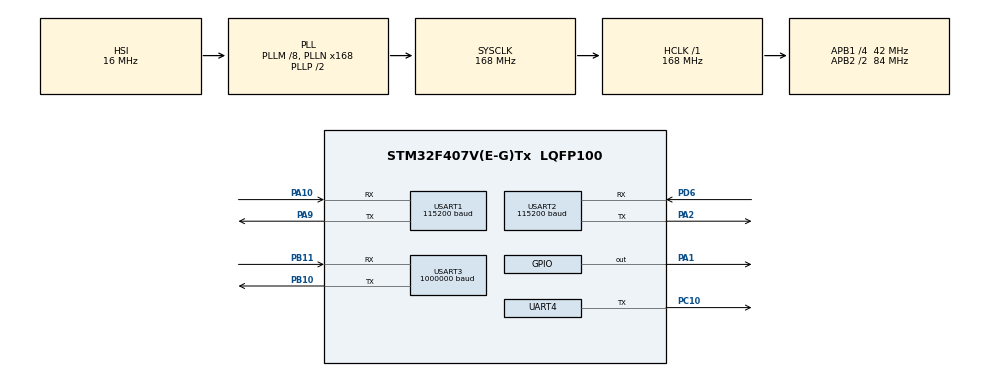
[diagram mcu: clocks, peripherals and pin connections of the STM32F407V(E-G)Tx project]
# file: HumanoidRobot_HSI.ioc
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Dma.Request0=USART1_RX
Dma.Request1=USART2_RX
Dma.Request2=USART3_TX
Dma.Request3=USART3_RX
Dma.USART1_RX.0.Direction=DMA_PERIPH_TO_MEMORY
Dma.USART1_RX.0.FIFOMode=DMA_FIFOMODE_DISABLE
Dma.USART1_RX.0.Instance=DMA2_Stream2
Dma.USART1_RX.0.MemDataAlignment=DMA_MDATAALIGN_BYTE
Dma.USART1_RX.0.MemInc=DMA_MINC_ENABLE
Dma.USART1_RX.0.Mode=DMA_CIRCULAR
Dma.USART1_RX.0.PeriphDataAlignment=DMA_PDATAALIGN_BYTE
Dma.USART1_RX.0.PeriphInc=DMA_PINC_DISABLE
Dma.USART1_RX.0.Priority=DMA_PRIORITY_HIGH
Dma.USART2_RX.1.Direction=DMA_PERIPH_TO_MEMORY
Dma.USART2_RX.1.FIFOMode=DMA_FIFOMODE_DISABLE
Dma.USART2_RX.1.Instance=DMA1_Stream5
Dma.USART2_RX.1.MemDataAlignment=DMA_MDATAALIGN_BYTE
Dma.USART2_RX.1.MemInc=DMA_MINC_ENABLE
Dma.USART2_RX.1.Mode=DMA_CIRCULAR
Dma.USART2_RX.1.PeriphDataAlignment=DMA_PDATAALIGN_BYTE
Dma.USART2_RX.1.PeriphInc=DMA_PINC_DISABLE
Dma.USART2_RX.1.Priority=DMA_PRIORITY_MEDIUM
Dma.USART3_TX.2.Direction=DMA_MEMORY_TO_PERIPH
Dma.USART3_TX.2.FIFOMode=DMA_FIFOMODE_DISABLE
Dma.USART3_TX.2.Instance=DMA1_Stream3
Dma.USART3_TX.2.MemDataAlignment=DMA_MDATAALIGN_BYTE
Dma.USART3_TX.2.MemInc=DMA_MINC_ENABLE
Dma.USART3_TX.2.Mode=DMA_NORMAL
Dma.USART3_TX.2.PeriphDataAlignment=DMA_PDATAALIGN_BYTE
Dma.USART3_TX.2.PeriphInc=DMA_PINC_DISABLE
Dma.USART3_TX.2.Priority=DMA_PRIORITY_MEDIUM
Dma.USART3_RX.3.Direction=DMA_PERIPH_TO_MEMORY
Dma.USART3_RX.3.FIFOMode=DMA_FIFOMODE_DISABLE
Dma.USART3_RX.3.Instance=DMA1_Stream1
Dma.USART3_RX.3.MemDataAlignment=DMA_MDATAALIGN_BYTE
Dma.USART3_RX.3.MemInc=DMA_MINC_ENABLE
Dma.USART3_RX.3.Mode=DMA_CIRCULAR
Dma.USART3_RX.3.PeriphDataAlignment=DMA_PDATAALIGN_BYTE
Dma.USART3_RX.3.PeriphInc=DMA_PINC_DISABLE
Dma.USART3_RX.3.Priority=DMA_PRIORITY_MEDIUM
FREERTOS.Tasks01=IMUTask,32,256,IMU_Task,As external,NULL,Dynamic,NULL,NULL;CameraTask,32,384,Camera_Task,As external,NULL,Dynamic,NULL,NULL;ServoTask,24,256,ServoTask,As external,NULL,Dynamic,NULL,NULL;RobotTask,24,512,RobotTask,As external,NULL,Dynamic,NULL,NULL;DebugTask,8,256,Debug_Task,As external,NULL,Dynamic,NULL,NULL
FREERTOS.configTOTAL_HEAP_SIZE=20480
Mcu.Family=STM32F4
Mcu.Name=STM32F407V(E-G)Tx
Mcu.Package=LQFP100
NVIC.DMA1_Stream1_IRQn=true\:5\:0\:false\:false\:true\:true\:false\:true\:true
NVIC.DMA1_Stream3_IRQn=true\:5\:0\:false\:false\:true\:true\:false\:true\:true
NVIC.DMA1_Stream5_IRQn=true\:5\:0\:false\:false\:true\:true\:false\:true\:true
NVIC.DMA2_Stream2_IRQn=true\:5\:0\:false\:false\:true\:true\:false\:true\:true
NVIC.PriorityGroup=NVIC_PRIORITYGROUP_4
NVIC.TIM6_DAC_IRQn=true\:15\:0\:false\:false\:true\:false\:false\:true\:true
NVIC.TimeBase=TIM6_DAC_IRQn
NVIC.TimeBaseIP=TIM6
NVIC.USART1_IRQn=true\:5\:0\:false\:false\:true\:false\:true\:true\:true
NVIC.USART2_IRQn=true\:5\:0\:false\:false\:true\:false\:true\:true\:true
NVIC.USART3_IRQn=true\:5\:0\:false\:false\:true\:false\:true\:true\:true
PA1.GPIO_PuPd=GPIO_PULLUP
PA1.PinState=GPIO_PIN_SET
PA1.Signal=GPIO_Output
PA10.Mode=Asynchronous
PA10.Signal=USART1_RX
PA13.Mode=Serial_Wire
PA13.Signal=SYS_JTMS-SWDIO
PA14.Mode=Serial_Wire
PA14.Signal=SYS_JTCK-SWCLK
PA2.Mode=Asynchronous
PA2.Signal=USART2_TX
PD6.Mode=Asynchronous
PD6.Signal=USART2_RX
PA9.Mode=Asynchronous
PA9.Signal=USART1_TX
PB10.Mode=Asynchronous
PB10.Signal=USART3_TX
PB11.Mode=Asynchronous
PB11.Signal=USART3_RX
PC10.Mode=Asynchronous
PC10.Signal=UART4_TX
PH0-OSC_IN.Mode=HSE-External-Oscillator
PH0-OSC_IN.Signal=RCC_OSC_IN
PH1-OSC_OUT.Mode=HSE-External-Oscillator
PH1-OSC_OUT.Signal=RCC_OSC_OUT
ProjectManager.HeapSize=0x200
ProjectManager.StackSize=0x800
ProjectManager.TargetToolchain=MDK-ARM V5.32
RCC.48MHZClocksFreq_Value=84000000
RCC.AHBFreq_Value=168000000
RCC.APB1CLKDivider=RCC_HCLK_DIV4
RCC.APB1Freq_Value=42000000
RCC.APB1TimFreq_Value=84000000
RCC.APB2CLKDivider=RCC_HCLK_DIV2
RCC.APB2Freq_Value=84000000
RCC.APB2TimFreq_Value=168000000
RCC.CortexFreq_Value=168000000
RCC.HCLKFreq_Value=168000000
RCC.HSE_VALUE=12000000
RCC.HSI_VALUE=16000000
RCC.LSE_VALUE=32768
RCC.PLLM=8
RCC.PLLN=168
RCC.PLLQ=4
RCC.PLLSourceVirtual=RCC_PLLSOURCE_HSI
RCC.SYSCLKFreq_VALUE=168000000
RCC.SYSCLKSource=RCC_SYSCLKSOURCE_PLLCLK
RCC.VCOOutputFreq_Value=336000000
UART4.BaudRate=115200
UART4.VirtualMode=Asynchronous
UART4.Mode=MODE_TX
USART1.BaudRate=115200
USART1.VirtualMode=VM_ASYNC
USART2.BaudRate=115200
USART2.VirtualMode=VM_ASYNC
USART3.BaudRate=1000000
USART3.VirtualMode=VM_ASYNC
VP_FREERTOS_VS_CMSIS_V2.Mode=CMSIS_V2
VP_SYS_VS_tim6.Mode=TIM6
board=custom

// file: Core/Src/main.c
/* USER CODE BEGIN Header */
/**
  ******************************************************************************
  * @file           : main.c
  * @brief          : Main program body
  ******************************************************************************
  * @attention
  *
  * Copyright (c) 2026 STMicroelectronics.
  * All rights reserved.
  *
  * This software is licensed under terms that can be found in the LICENSE file
  * in the root directory of this software component.
  * If no LICENSE file comes with this software, it is provided AS-IS.
  *
  ******************************************************************************
  */
/* USER CODE END Header */
#include "main.h"
#include "cmsis_os.h"
#include "dma.h"
#include "usart.h"
#include "gpio.h"

void SystemClock_Config(void);
void MX_FREERTOS_Init(void);

int main(void)
{

  /* MCU Configuration--------------------------------------------------------*/

  /* Reset of all peripherals, Initializes the Flash interface and the Systick. */
  HAL_Init();

  /* Configure the system clock */
  SystemClock_Config();

  /* Initialize all configured peripherals */
  MX_GPIO_Init();
  MX_DMA_Init();
  MX_USART1_UART_Init();
  MX_USART2_UART_Init();
  MX_USART3_UART_Init();
  MX_UART4_Init();
  /* USER CODE BEGIN 2 */
    HAL_UART_Transmit(&huart4, (uint8_t *)"UART4 OK\r\n", 10U, 100U);
    {
      static const char bootInfo[] =
        "[BOOT] HumanoidRobot_HSI PA1=HIGH DEBUG=PC10\r\n"
        "[CLOCK] HSI->PLL SYSCLK=168MHz APB1=42MHz APB2=84MHz\r\n";
      HAL_UART_Transmit(&huart4, (uint8_t *)bootInfo,
                        (uint16_t)(sizeof(bootInfo) - 1U), 100U);
    }
  /* USER CODE END 2 */

  /* Init scheduler */
  osKernelInitialize();  /* Call init function for freertos objects (in cmsis_os2.c) */
  MX_FREERTOS_Init();

  /* Start scheduler */
  osKernelStart();

  /* We should never get here as control is now taken by the scheduler */

  /* Infinite loop */
  while (1)
  {

  }
}

void SystemClock_Config(void)
{
  RCC_OscInitTypeDef RCC_OscInitStruct = {0};
  RCC_ClkInitTypeDef RCC_ClkInitStruct = {0};

  /** Configure the main internal regulator output voltage
  */
  __HAL_RCC_PWR_CLK_ENABLE();
  __HAL_PWR_VOLTAGESCALING_CONFIG(PWR_REGULATOR_VOLTAGE_SCALE1);

  /** Initializes the RCC Oscillators according to the specified parameters
  * in the RCC_OscInitTypeDef structure.
  */
  RCC_OscInitStruct.OscillatorType = RCC_OSCILLATORTYPE_HSI;
  RCC_OscInitStruct.HSIState = RCC_HSI_ON;
  RCC_OscInitStruct.HSICalibrationValue = RCC_HSICALIBRATION_DEFAULT;
  RCC_OscInitStruct.PLL.PLLState = RCC_PLL_ON;
  RCC_OscInitStruct.PLL.PLLSource = RCC_PLLSOURCE_HSI;
  RCC_OscInitStruct.PLL.PLLM = 8;
  RCC_OscInitStruct.PLL.PLLN = 168;
  RCC_OscInitStruct.PLL.PLLP = RCC_PLLP_DIV2;
  RCC_OscInitStruct.PLL.PLLQ = 4;
  if (HAL_RCC_OscConfig(&RCC_OscInitStruct) != HAL_OK)
  {
    Error_Handler();
  }

  /** Initializes the CPU, AHB and APB buses clocks
  */
  RCC_ClkInitStruct.ClockType = RCC_CLOCKTYPE_HCLK|RCC_CLOCKTYPE_SYSCLK
                              |RCC_CLOCKTYPE_PCLK1|RCC_CLOCKTYPE_PCLK2;
  RCC_ClkInitStruct.SYSCLKSource = RCC_SYSCLKSOURCE_PLLCLK;
  RCC_ClkInitStruct.AHBCLKDivider = RCC_SYSCLK_DIV1;
  RCC_ClkInitStruct.APB1CLKDivider = RCC_HCLK_DIV4;
  RCC_ClkInitStruct.APB2CLKDivider = RCC_HCLK_DIV2;

  if (HAL_RCC_ClockConfig(&RCC_ClkInitStruct, FLASH_LATENCY_5) != HAL_OK)
  {
    Error_Handler();
  }
}

void HAL_TIM_PeriodElapsedCallback(TIM_HandleTypeDef *htim)
{
  if (htim->Instance == TIM6)
  {
    HAL_IncTick();
  }
}

void Error_Handler(void)
{
  /* USER CODE BEGIN Error_Handler_Debug */
  /* User can add his own implementation to report the HAL error return state */
  __disable_irq();
  /*
   * 此处可能在FreeRTOS调度器启动前执行，也可能发生在调试串口互斥量创建前。
   * 因此不要在Error_Handler()中调用Debug_Printf()，避免故障处理再次阻塞。
   */
  while (1)
  {
  }
  /* USER CODE END Error_Handler_Debug */
}

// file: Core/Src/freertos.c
/* USER CODE BEGIN Header */
/**
  ******************************************************************************
  * File Name          : freertos.c
  * Description        : Code for freertos applications
  ******************************************************************************
  * @attention
  *
  * Copyright (c) 2026 STMicroelectronics.
  * All rights reserved.
  *
  * This software is licensed under terms that can be found in the LICENSE file
  * in the root directory of this software component.
  * If no LICENSE file comes with this software, it is provided AS-IS.
  *
  ******************************************************************************
  */
/* USER CODE END Header */

#include "FreeRTOS.h"
#include "task.h"
#include "main.h"
#include "cmsis_os.h"

/* USER CODE BEGIN Includes */
#include "app_tasks.h"
/* USER CODE END Includes */

/* Definitions for IMUTask */
osThreadId_t IMUTaskHandle;
const osThreadAttr_t IMUTask_attributes = {
  .name = "IMUTask",
  .stack_size = 256 * 4,
  .priority = (osPriority_t) osPriorityAboveNormal,
};
/* Definitions for CameraTask */
osThreadId_t CameraTaskHandle;
const osThreadAttr_t CameraTask_attributes = {
  .name = "CameraTask",
  .stack_size = 384 * 4,
  .priority = (osPriority_t) osPriorityAboveNormal,
};
/* Definitions for ServoTask */
osThreadId_t ServoTaskHandle;
const osThreadAttr_t ServoTask_attributes = {
  .name = "ServoTask",
  .stack_size = 256 * 4,
  .priority = (osPriority_t) osPriorityNormal,
};
/* Definitions for RobotTask */
osThreadId_t RobotTaskHandle;
const osThreadAttr_t RobotTask_attributes = {
  .name = "RobotTask",
  .stack_size = 512 * 4,
  .priority = (osPriority_t) osPriorityNormal,
};
/* Definitions for DebugTask */
osThreadId_t DebugTaskHandle;
const osThreadAttr_t DebugTask_attributes = {
  .name = "DebugTask",
  .stack_size = 384 * 4, /* 接收诊断增加printf调用深度，保留栈余量。 */
  .priority = (osPriority_t) osPriorityLow,
};

extern void IMU_Task(void *argument);
extern void Camera_Task(void *argument);
extern void ServoTask(void *argument);
extern void RobotTask(void *argument);
extern void Debug_Task(void *argument);

void MX_FREERTOS_Init(void); /* (MISRA C 2004 rule 8.1) */

void MX_FREERTOS_Init(void) {
  /* USER CODE BEGIN Init */
  /*
   * 创建 UART 接收队列和调试互斥量。
   * 队列必须先于任务创建，确保调度器启动后任务立即可安全使用。
   */
  App_RTOS_ObjectsInit();
  /* USER CODE END Init */

  /* Create the thread(s) */
  /* creation of IMUTask */
  IMUTaskHandle = osThreadNew(IMU_Task, NULL, &IMUTask_attributes);

  /* creation of CameraTask */
  CameraTaskHandle = osThreadNew(Camera_Task, NULL, &CameraTask_attributes);

  /* creation of ServoTask */
  ServoTaskHandle = osThreadNew(ServoTask, NULL, &ServoTask_attributes);

  /* creation of RobotTask */
  RobotTaskHandle = osThreadNew(RobotTask, NULL, &RobotTask_attributes);

  /* creation of DebugTask */
  DebugTaskHandle = osThreadNew(Debug_Task, NULL, &DebugTask_attributes);

  /* USER CODE BEGIN RTOS_THREADS */
  /*
   * CMSIS-RTOS2 的 osThreadId_t 在本移植层中对应 FreeRTOS TaskHandle_t。
   * 将句柄交给 UART DMA 层后，IDLE ISR 才能精确通知对应任务。
   */
  if (RobotTaskHandle == NULL)
  {
    Error_Handler();
  }

  App_RTOS_BindTaskHandles((TaskHandle_t)IMUTaskHandle,
                           (TaskHandle_t)CameraTaskHandle,
                           (TaskHandle_t)ServoTaskHandle,
                           (TaskHandle_t)DebugTaskHandle);
  /* USER CODE END RTOS_THREADS */

}

__weak void IMU_Task(void *argument)
{
  for(;;)
  {
    osDelay(1);
  }
}
